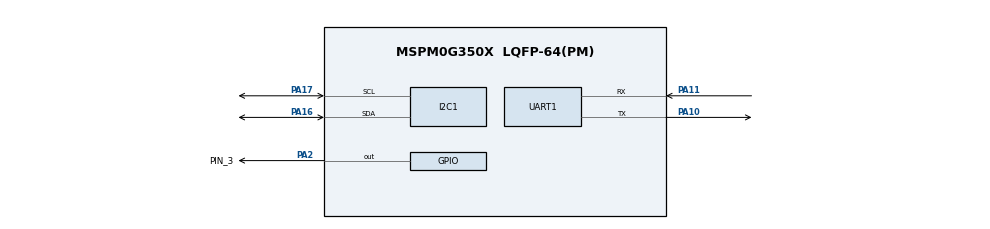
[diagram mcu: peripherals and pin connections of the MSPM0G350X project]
/**
 * @cliArgs --device "MSPM0G350X" --part "Default" --package "LQFP-64(PM)" --product "mspm0_sdk@2.02.00.05"
 * @versions {"tool":"1.21.1+3772"}
 */

/**
 * Import the modules used in this configuration.
 */
const GPIO    = scripting.addModule("/ti/driverlib/GPIO", {}, false);
const GPIO1   = GPIO.addInstance();
const GPIO2   = GPIO.addInstance();
const GPIO3   = GPIO.addInstance();
const GPIO4   = GPIO.addInstance();
const GPIO5   = GPIO.addInstance();
const I2C     = scripting.addModule("/ti/driverlib/I2C", {}, false);
const I2C1    = I2C.addInstance();
const PWM     = scripting.addModule("/ti/driverlib/PWM", {}, false);
const PWM1    = PWM.addInstance();
const PWM2    = PWM.addInstance();
const SYSCTL  = scripting.addModule("/ti/driverlib/SYSCTL");
const SYSTICK = scripting.addModule("/ti/driverlib/SYSTICK");
const UART    = scripting.addModule("/ti/driverlib/UART", {}, false);
const UART1   = UART.addInstance();

/**
 * Write custom configuration values to the imported modules.
 */
GPIO1.$name                              = "GRAY_6CH";
GPIO1.port                               = "PORTA";
GPIO1.associatedPins.create(6);
GPIO1.associatedPins[0].$name            = "GRAY_L2";
GPIO1.associatedPins[0].direction        = "INPUT";
GPIO1.associatedPins[0].internalResistor = "PULL_UP";
GPIO1.associatedPins[0].assignedPin      = "24";
GPIO1.associatedPins[1].$name            = "GRAY_L1";
GPIO1.associatedPins[1].direction        = "INPUT";
GPIO1.associatedPins[1].assignedPin      = "25";
GPIO1.associatedPins[1].internalResistor = "PULL_UP";
GPIO1.associatedPins[2].$name            = "GRAY_M1";
GPIO1.associatedPins[2].direction        = "INPUT";
GPIO1.associatedPins[2].internalResistor = "PULL_UP";
GPIO1.associatedPins[2].assignedPin      = "26";
GPIO1.associatedPins[3].$name            = "GRAY_M2";
GPIO1.associatedPins[3].direction        = "INPUT";
GPIO1.associatedPins[3].internalResistor = "PULL_UP";
GPIO1.associatedPins[3].assignedPin      = "27";
GPIO1.associatedPins[4].$name            = "GRAY_R1";
GPIO1.associatedPins[4].direction        = "INPUT";
GPIO1.associatedPins[4].internalResistor = "PULL_UP";
GPIO1.associatedPins[4].assignedPin      = "28";
GPIO1.associatedPins[5].$name            = "GRAY_R2";
GPIO1.associatedPins[5].direction        = "INPUT";
GPIO1.associatedPins[5].assignedPin      = "29";
GPIO1.associatedPins[5].internalResistor = "PULL_UP";

const Board = scripting.addModule("/ti/driverlib/Board", {}, false);

GPIO2.$name                         = "RED_GPIO";
GPIO2.associatedPins[0].$name       = "PIN_0";
GPIO2.associatedPins[0].ioStructure = "SD";

GPIO3.$name                               = "MODE_GPIO";
GPIO3.port                                = "PORTA";
GPIO3.associatedPins[0].$name             = "PIN_1";
GPIO3.associatedPins[0].ioStructure       = "SDW";
GPIO3.associatedPins[0].interruptEn       = true;
GPIO3.associatedPins[0].pubChanID         = 1;
GPIO3.associatedPins[0].polarity          = "FALL";
GPIO3.associatedPins[0].interruptPriority = "1";
GPIO3.associatedPins[0].internalResistor  = "PULL_UP";
GPIO3.associatedPins[0].direction         = "INPUT";

GPIO4.$name                               = "CONF_GPIO";
GPIO4.associatedPins[0].$name             = "PIN_2";
GPIO4.associatedPins[0].direction         = "INPUT";
GPIO4.associatedPins[0].ioStructure       = "SD";
GPIO4.associatedPins[0].internalResistor  = "PULL_UP";
GPIO4.associatedPins[0].interruptEn       = true;
GPIO4.associatedPins[0].interruptPriority = "1";
GPIO4.associatedPins[0].polarity          = "FALL";
GPIO4.associatedPins[0].pubChanID         = 2;

GPIO5.$name                          = "BUZZER_GPIO";
GPIO5.associatedPins[0].$name        = "PIN_3";
GPIO5.associatedPins[0].ioStructure  = "SD";
GPIO5.associatedPins[0].initialValue = "SET";
GPIO5.associatedPins[0].pin.$assign  = "PA2";

I2C1.$name                         = "I2C_0";
I2C1.basicEnableController         = true;
I2C1.peripheral.$assign            = "I2C1";
I2C1.peripheral.sdaPin.$assign     = "PA16";
I2C1.peripheral.sclPin.$assign     = "PA17";
I2C1.sdaPinConfig.$name            = "ti_driverlib_gpio_GPIOPinGeneric6";
I2C1.sdaPinConfig.enableConfig     = true;
I2C1.sdaPinConfig.internalResistor = "PULL_UP";
I2C1.sclPinConfig.$name            = "ti_driverlib_gpio_GPIOPinGeneric7";
I2C1.sclPinConfig.enableConfig     = true;
I2C1.sclPinConfig.internalResistor = "PULL_UP";

PWM1.timerStartTimer                    = true;
PWM1.pwmMode                            = "EDGE_ALIGN_UP";
PWM1.$name                              = "PWM_AIN";
PWM1.timerCount                         = 1599;
PWM1.peripheral.$assign                 = "TIMG0";
PWM1.PWM_CHANNEL_0.$name                = "ti_driverlib_pwm_PWMTimerCC0";
PWM1.PWM_CHANNEL_1.$name                = "ti_driverlib_pwm_PWMTimerCC2";
PWM1.ccp0PinConfig.$name                = "ti_driverlib_gpio_GPIOPinGeneric2";
PWM1.ccp0PinConfig.direction            = scripting.forceWrite("OUTPUT");
PWM1.ccp0PinConfig.hideOutputInversion  = scripting.forceWrite(false);
PWM1.ccp0PinConfig.onlyInternalResistor = scripting.forceWrite(false);
PWM1.ccp0PinConfig.passedPeripheralType = scripting.forceWrite("Digital");
PWM1.ccp1PinConfig.direction            = scripting.forceWrite("OUTPUT");
PWM1.ccp1PinConfig.hideOutputInversion  = scripting.forceWrite(false);
PWM1.ccp1PinConfig.onlyInternalResistor = scripting.forceWrite(false);
PWM1.ccp1PinConfig.passedPeripheralType = scripting.forceWrite("Digital");
PWM1.ccp1PinConfig.$name                = "ti_driverlib_gpio_GPIOPinGeneric0";

PWM2.timerStartTimer                    = true;
PWM2.pwmMode                            = "EDGE_ALIGN_UP";
PWM2.$name                              = "PWM_BIN";
PWM2.timerCount                         = 1599;
PWM2.peripheral.$assign                 = "TIMG6";
PWM2.PWM_CHANNEL_0.$name                = "ti_driverlib_pwm_PWMTimerCC0_COPY";
PWM2.PWM_CHANNEL_1.$name                = "ti_driverlib_pwm_PWMTimerCC2_COPY";
PWM2.ccp0PinConfig.direction            = scripting.forceWrite("OUTPUT");
PWM2.ccp0PinConfig.hideOutputInversion  = scripting.forceWrite(false);
PWM2.ccp0PinConfig.onlyInternalResistor = scripting.forceWrite(false);
PWM2.ccp0PinConfig.passedPeripheralType = scripting.forceWrite("Digital");
PWM2.ccp0PinConfig.$name                = "ti_driverlib_gpio_GPIOPinGeneric2_COPY";
PWM2.ccp1PinConfig.direction            = scripting.forceWrite("OUTPUT");
PWM2.ccp1PinConfig.hideOutputInversion  = scripting.forceWrite(false);
PWM2.ccp1PinConfig.onlyInternalResistor = scripting.forceWrite(false);
PWM2.ccp1PinConfig.passedPeripheralType = scripting.forceWrite("Digital");
PWM2.ccp1PinConfig.$name                = "ti_driverlib_gpio_GPIOPinGeneric0_COPY";

SYSCTL.forceDefaultClkConfig = true;

SYSTICK.periodEnable  = true;
SYSTICK.systickEnable = true;
SYSTICK.period        = 320000;

UART1.$name                            = "DEBUG_UART";
UART1.targetBaudRate                   = 115200;
UART1.peripheral.$assign               = "UART0";
UART1.peripheral.rxPin.$assign         = "PA11";
UART1.peripheral.txPin.$assign         = "PA10";
UART1.txPinConfig.direction            = scripting.forceWrite("OUTPUT");
UART1.txPinConfig.hideOutputInversion  = scripting.forceWrite(false);
UART1.txPinConfig.onlyInternalResistor = scripting.forceWrite(false);
UART1.txPinConfig.passedPeripheralType = scripting.forceWrite("Digital");
UART1.txPinConfig.$name                = "ti_driverlib_gpio_GPIOPinGeneric4";
UART1.rxPinConfig.hideOutputInversion  = scripting.forceWrite(false);
UART1.rxPinConfig.onlyInternalResistor = scripting.forceWrite(false);
UART1.rxPinConfig.passedPeripheralType = scripting.forceWrite("Digital");
UART1.rxPinConfig.$name                = "ti_driverlib_gpio_GPIOPinGeneric5";

/**
 * Pinmux solution for unlocked pins/peripherals. This ensures that minor changes to the automatic solver in a future
 * version of the tool will not impact the pinmux you originally saw.  These lines can be completely deleted in order to
 * re-solve from scratch.
 */
GPIO1.associatedPins[0].pin.$suggestSolution = "PA24";
GPIO1.associatedPins[1].pin.$suggestSolution = "PA25";
GPIO1.associatedPins[2].pin.$suggestSolution = "PA26";
GPIO1.associatedPins[3].pin.$suggestSolution = "PA27";
GPIO1.associatedPins[4].pin.$suggestSolution = "PA28";
GPIO1.associatedPins[5].pin.$suggestSolution = "PA29";
Board.peripheral.$suggestSolution            = "DEBUGSS";
Board.peripheral.swclkPin.$suggestSolution   = "PA20";
Board.peripheral.swdioPin.$suggestSolution   = "PA19";
GPIO2.associatedPins[0].pin.$suggestSolution = "PB14";
GPIO3.associatedPins[0].pin.$suggestSolution = "PA18";
GPIO4.associatedPins[0].pin.$suggestSolution = "PB13";
PWM1.peripheral.ccp0Pin.$suggestSolution     = "PA12";
PWM1.peripheral.ccp1Pin.$suggestSolution     = "PA13";
PWM2.peripheral.ccp0Pin.$suggestSolution     = "PA21";
PWM2.peripheral.ccp1Pin.$suggestSolution     = "PA22";
SYSCTL.peripheral.$suggestSolution           = "SYSCTL";
